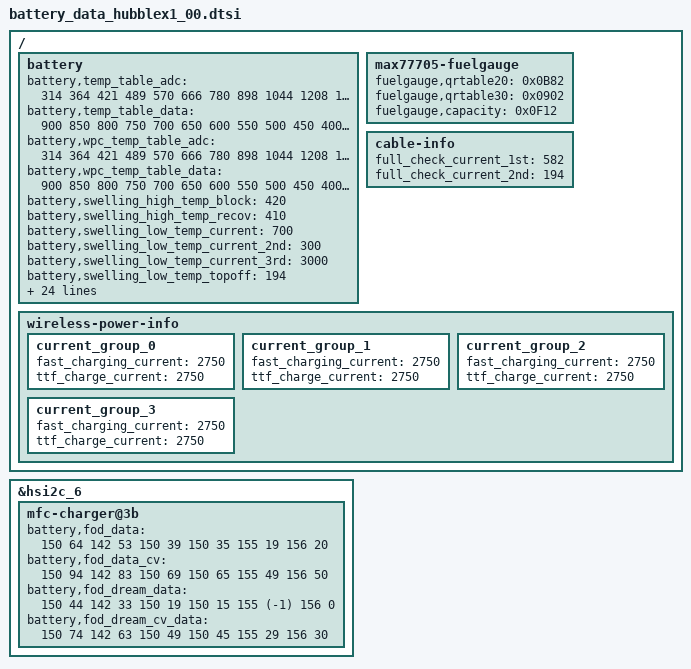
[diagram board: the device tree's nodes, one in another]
/* SAMSUNG UNIVERSAL9830 board device tree source
 *
 * Copyright (c) 2018 Samsung Electronics Co., Ltd.
 *		http://www.samsung.com
 *
 * This program is free software; you can redistribute it and/or modify
 * it under the terms of the GNU General Public License version 2 as
 * published by the Free Software Foundation.
 */

#include "battery_data_hubble_common.dtsi"

/ {
	fragment@battery {
		target-path = "/";
		__overlay__ {
			battery {
				battery,temp_table_adc = <
					314 364 421 489 570 666 780 898 1044 1208 1396 1598 1817
					2049 2286 2518 2752 2965 3159 3341 3494 3606 3704>;

				battery,temp_table_data = <
					900 850 800 750 700 650 600 550 500 450 400 350 300 250
					200 150 100 50 0 (-50) (-100) (-150) (-200)>;

				battery,wpc_temp_table_adc = <
					314 364 421 489 570 666 780 898 1044 1208 1396 1598 1817
					2049 2286 2518 2752 2965 3159 3341 3494 3606 3704>;

				battery,wpc_temp_table_data = <
					900 850 800 750 700 650 600 550 500 450 400 350 300 250
					200 150 100 50 0 (-50) (-100) (-150) (-200)>;

				battery,swelling_high_temp_block = <420>;
				battery,swelling_high_temp_recov = <410>;

				/* swelling current */
				battery,swelling_low_temp_current = <700>;	/* 0.3C */
				battery,swelling_low_temp_current_2nd = <300>;	/* 0.3C */
				battery,swelling_low_temp_current_3rd = <3000>;	/* 0.72C */
				battery,swelling_low_temp_topoff = <194>;	/* 0.05C */
				battery,swelling_high_temp_current = <1050>;	/* 0.45C */
				battery,swelling_high_temp_topoff = <194>;	/* 0.05C */
				battery,swelling_wc_high_temp_current = <700>;	/* 0.3C */
				battery,swelling_wc_low_temp_current = <700>;	/* 0.3C */
 				battery,swelling_wc_low_temp_current_2nd = <300>;	/* 0.3C */
				battery,swelling_wc_low_temp_current_3rd = <3000>;	/* 0.72C */

				/* step charging option */
				battery,step_charging_type = <0x3E>;
				battery,step_charging_charge_power = <12000>;
				battery,step_charging_condition = <55 100>;
				battery,step_charging_condition_curr = <2850 2400>;
				battery,step_charging_current = <3150 2850>;
				battery,step_charging_float_voltage = <4210 4380>;


				/* direct step charging option */
				battery,dc_step_chg_type = <0x6B>; /* origin(0x6B) */
				battery,dc_step_chg_charge_power = <22000>;
				battery,dc_step_chg_step = <3>;
				battery,dc_step_chg_cond_vol = <4110 4210 4380>; /* STEP_CHARGING_CONDITION_VOLTAGE */ 
				battery,dc_step_chg_cond_iin = <1530 1220 0>; /* STEP_CHARGING_CONDITION_INPUT_CURRENT */
				battery,dc_step_chg_iin_check_cnt = <3>;
				battery,dc_step_chg_cond_soc = <25 55 100>; /* STEP_CHARGING_CONDITION_SOC */
				battery,dc_step_chg_val_vfloat = <4110 4210 4380>; /* STEP_CHARGING_CONDITION_FLOAT_VOLTAGE */
				battery,dc_step_chg_val_iout = <4690 3600 2880>;

				battery,snkcap_data = /bits/ 8 <0x04 0x2C 0x91 0x01 0x36 0xC8 0xD0 0x02 0x00 0xC8 0x90
								0x41 0x8B 0x2F 0x21 0xDC 0xC0>;
			};

			max77705-fuelgauge {
				status = "okay";
				fuelgauge,qrtable20 = <0x0B82>;
				fuelgauge,qrtable30 = <0x0902>;
				fuelgauge,capacity = <0x0F12>;
			};

			cable-info {
				full_check_current_1st = <582>;
				full_check_current_2nd = <194>;
			};

			wireless-power-info {
				current_group_0 {
					fast_charging_current = <2750>;
					ttf_charge_current = <2750>;
				};
				current_group_1 {
					fast_charging_current = <2750>;
					ttf_charge_current = <2750>;
				};
				current_group_2 {
					fast_charging_current = <2750>;
					ttf_charge_current = <2750>;
				};
				current_group_3 {
					fast_charging_current = <2750>;
					ttf_charge_current = <2750>;
				};
			};
		}; /* end of __overlay__ */
	}; /* end of fragment */
};

&hsi2c_6 {
	mfc-charger@3b {
		battery,fod_data = <150 64 142 53 150 39 150 35 155 19 156 20>;
		battery,fod_data_cv = <150 94 142 83 150 69 150 65 155 49 156 50>;
		/delete-property/ battery,fod_hero_5v_data;
		battery,fod_dream_data = <150 44 142 33 150 19 150 15 155 (-1) 156 0>;
		battery,fod_dream_cv_data = <150 74 142 63 150 49 150 45 155 29 156 30>;
	};
};
